# R7FA6T2BD register map
Vendor: Renesas Electronics Corporation; Series: RA6; File version: 1.40.00
CPU: CM33 r0p4, little endian, MPU, FPU, VTOR, 4 interrupt priority bits, 96 interrupts
Registers are 32-bit, read-write, reset 0x0 unless marked. A register's access mark holds for its fields unless they carry their own. Offsets are from the block's base; [hi:lo] are bit positions; {n}, {i} and the like mark numbered series.

## FCACHE — Flash Cache
Base 0x4001C100
0x00 FCACHEE 16-bit — Flash Cache Enable Register
  [0] FCACHEEN — Flash Cache Enable
0x04 FCACHEIV 16-bit — Flash Cache Invalidate Register
  [0] FCACHEIV — Flash Cache Invalidate
0x1C FLWT 8-bit — Flash Wait Cycle Register
  [2:0] FLWT — Flash Wait Cycle
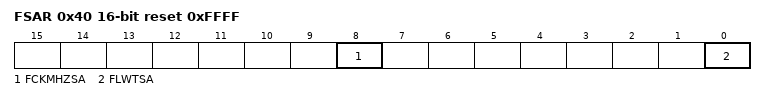
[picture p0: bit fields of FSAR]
0x40 FSAR 16-bit reset 0xFFFF — Flash Security Attribution Register
  [8] FCKMHZSA — FCKMHZ Security Attribution
  [0] FLWTSA — FLWT Security Attribution

## PORT0 — Port 0 Control Registers
Base 0x4001F000
Same registers: PORT2 0x4001F040, PORTA 0x4001F140
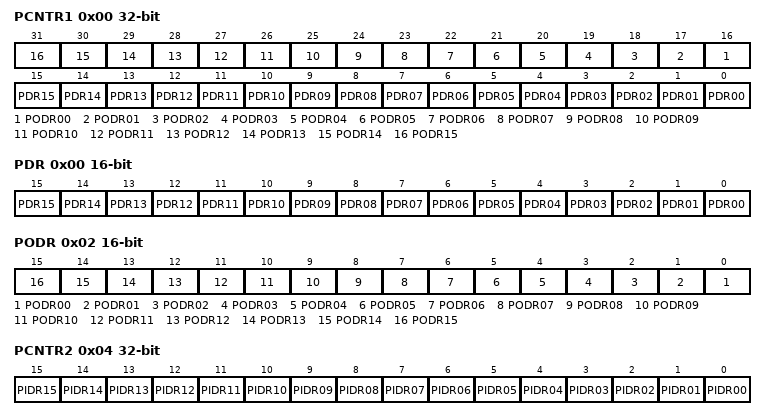
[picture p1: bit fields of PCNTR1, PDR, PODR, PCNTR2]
0x00 PCNTR1 — Port Control Register 1
  [n+16] PODR{n:02} (n=0..15) — Pmn Output Data
  [n] PDR{n:02} (n=0..15) — Pmn Direction
0x00 PDR 16-bit (alternate view of PCNTR1) — Port Control Register 1
  [n] PDR{n:02} (n=0..15) — Pmn Direction
0x02 PODR 16-bit (alternate view of PCNTR1) — Port Control Register 1
  [n] PODR{n:02} (n=0..15) — Pmn Output Data
0x04 PCNTR2 ro (reset mask 0xFFFF0000) — Port Control Register 2
  [n] PIDR{n:02} (n=0..15) — Pmn State
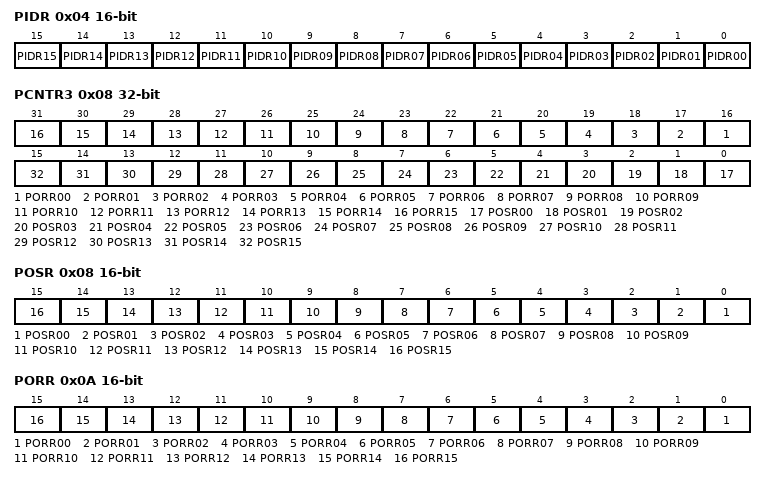
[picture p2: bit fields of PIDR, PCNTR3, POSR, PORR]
0x04 PIDR 16-bit ro reset not defined (alternate view of PCNTR2) — Port Control Register 2
  [n] PIDR{n:02} (n=0..15) — Pmn State
0x08 PCNTR3 wo — Port Control Register 3
  [n+16] PORR{n:02} (n=0..15) — Pmn Output Reset
  [n] POSR{n:02} (n=0..15) — Pmn Output Set
0x08 POSR 16-bit wo (alternate view of PCNTR3) — Port Control Register 3
  [n] POSR{n:02} (n=0..15) — Pmn Output Set
0x0A PORR 16-bit wo (alternate view of PCNTR3) — Port Control Register 3
  [n] PORR{n:02} (n=0..15) — Pmn Output Reset

## PORTB — Port B Control Registers
Base 0x4001F160
Same registers: PORTC 0x4001F180, PORTD 0x4001F1A0, PORTE 0x4001F1C0
Registers as PORT0; these are added or differ:
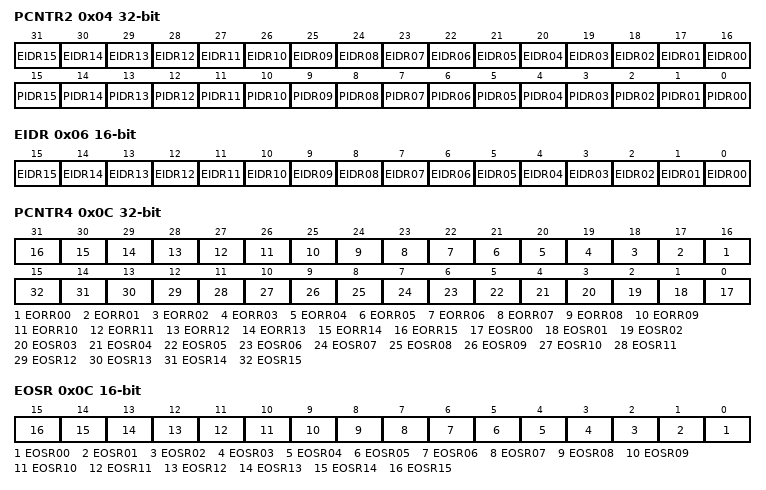
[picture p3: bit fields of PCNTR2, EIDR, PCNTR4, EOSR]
0x04 PCNTR2 ro (reset mask 0xFFFF0000) — Port Control Register 2
  [n+16] EIDR{n:02} (n=0..15) — Port Event Input Data
  [n] PIDR{n:02} (n=0..15) — Pmn State
0x06 EIDR 16-bit ro (alternate view of PCNTR2) — Port Control Register 2
  [n] EIDR{n:02} (n=0..15) — Port Event Input Data
0x0C PCNTR4 — Port Control Register 4
  [n+16] EORR{n:02} (n=0..15) — Pmn Event Output Reset
  [n] EOSR{n:02} (n=0..15) — Pmn Event Output Set
0x0C EOSR 16-bit (alternate view of PCNTR4) — Port Control Register 4
  [n] EOSR{n:02} (n=0..15) — Pmn Event Output Set
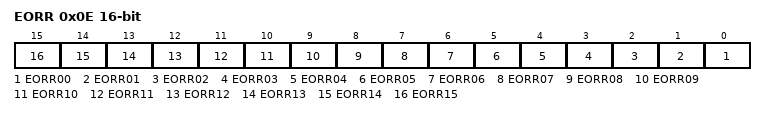
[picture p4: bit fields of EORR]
0x0E EORR 16-bit (alternate view of PCNTR4) — Port Control Register 4
  [n] EORR{n:02} (n=0..15) — Pmn Event Output Reset

## IIRFA — IIR filter accelerator
Base 0x40020000
0x00 IIRCPRCS ro — Channel Processing Status Register
  [15:0] CPRCS — Channel processing status bit
0x04 IIRCPRCFF ro — Channel Processing Completion Flag Register
  [15:0] CPRCFF — Channel processing completion flag
0x08 IIRORDYF ro — Output Data Preparation Completion Flag Register
  [15:0] ORDYF — Output data preparation completion flag
0x0C IIRCERRF ro — Operation Error Flag Register
  [15:0] CERRF — Operation error flag
0x10 IIROPCNT — Operation Control Register
  [2:0] RND — Setting for the rounding mode for addition and multiplication
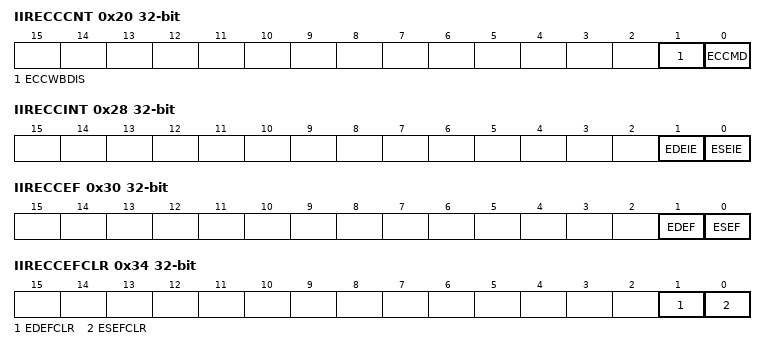
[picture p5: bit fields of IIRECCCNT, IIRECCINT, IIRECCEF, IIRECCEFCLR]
0x20 IIRECCCNT — ECC Control Register
  [1] ECCWBDIS — ECC,corrected data write,back disable bit
  [0] ECCMD — ECC setting bit
0x28 IIRECCINT — ECC Interrupt Enable Register
  [1] EDEIE — ECC 2-bit error interrupt enable bit
  [0] ESEIE — ECC 1-bit error interrupt enable bit
0x30 IIRECCEF ro — ECC Error Flag Register
  [1] EDEF — ECC 2-bit error flag
  [0] ESEF — ECC 1-bit error flag
0x34 IIRECCEFCLR wo — ECC Error Flag Clear Register
  [1] EDEFCLR — ECC 2-bit error status flag clear bit
  [0] ESEFCLR — ECC 1-bit error flag clear bit
0x38 IIRESEADR ro — ECC 1-bit Error Address Register
  [10:0] SEADR — Error address
0x3C IIREDEADR ro — ECC 2-bit Error Address Register
  [10:0] DEADR — Error address
{0x100+0x10*i} IIRCH{i}INP (i=0..15) wo reset not defined — Channel {i} Input Register
{0x104+0x10*i} IIRCH{i}OUT (i=0..15) ro — Channel {i} Output Register
{0x108+0x10*i} IIRCH{i}CNT (i=0..15) — Channel {i} Control Register
  [31:0] STGSEL — Stage selection bit
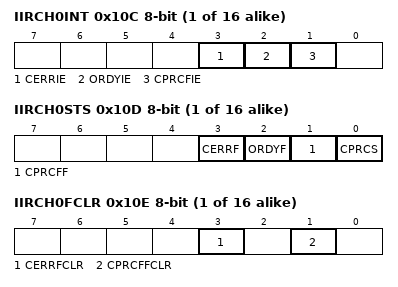
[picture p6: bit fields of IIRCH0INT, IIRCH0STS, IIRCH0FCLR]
{0x10C+0x10*i} IIRCH{i}INT (i=0..15) 8-bit — Channel {i} Interrupt Enable Register
  [3] CERRIE — Operation error interrupt enable bit
  [2] ORDYIE — Output data preparation completion interrupt enable bit
  [1] CPRCFIE — Channel processing completion interrupt enable bit
{0x10D+0x10*i} IIRCH{i}STS (i=0..15) 8-bit ro — Channel {i} Status Register
  [3] CERRF — Operation error flag
  [2] ORDYF — Output data preparation completion flag
  [1] CPRCFF — Channel processing completion flag
  [0] CPRCS — Channel processing status flag
{0x10E+0x10*i} IIRCH{i}FCLR (i=0..15) 8-bit wo — Channel {i} Flag Clear Register
  [3] CERRFCLR — Operation error flag clear bit
  [1] CPRCFFCLR — Channel processing completion flag clear bit
{0x400+0x20*i} IIRSTG{i}B0 (i=0..31) reset not defined — Stage {i} Coefficient b0 Register
{0x404+0x20*i} IIRSTG{i}B1 (i=0..31) reset not defined — Stage {i} Coefficient b1 Register
{0x408+0x20*i} IIRSTG{i}B2 (i=0..31) reset not defined — Stage {i} Coefficient b2 Register
{0x40C+0x20*i} IIRSTG{i}A1 (i=0..31) reset not defined — Stage {i} Coefficient a1 Register
{0x410+0x20*i} IIRSTG{i}A2 (i=0..31) reset not defined — Stage {i} Coefficient a2 Register
{0x414+0x20*i} IIRSTG{i}D0 (i=0..31) reset not defined — Stage {i} Delay Data D0 Register
{0x418+0x20*i} IIRSTG{i}D1 (i=0..31) reset not defined — Stage {i} Delay Data D1 Register
